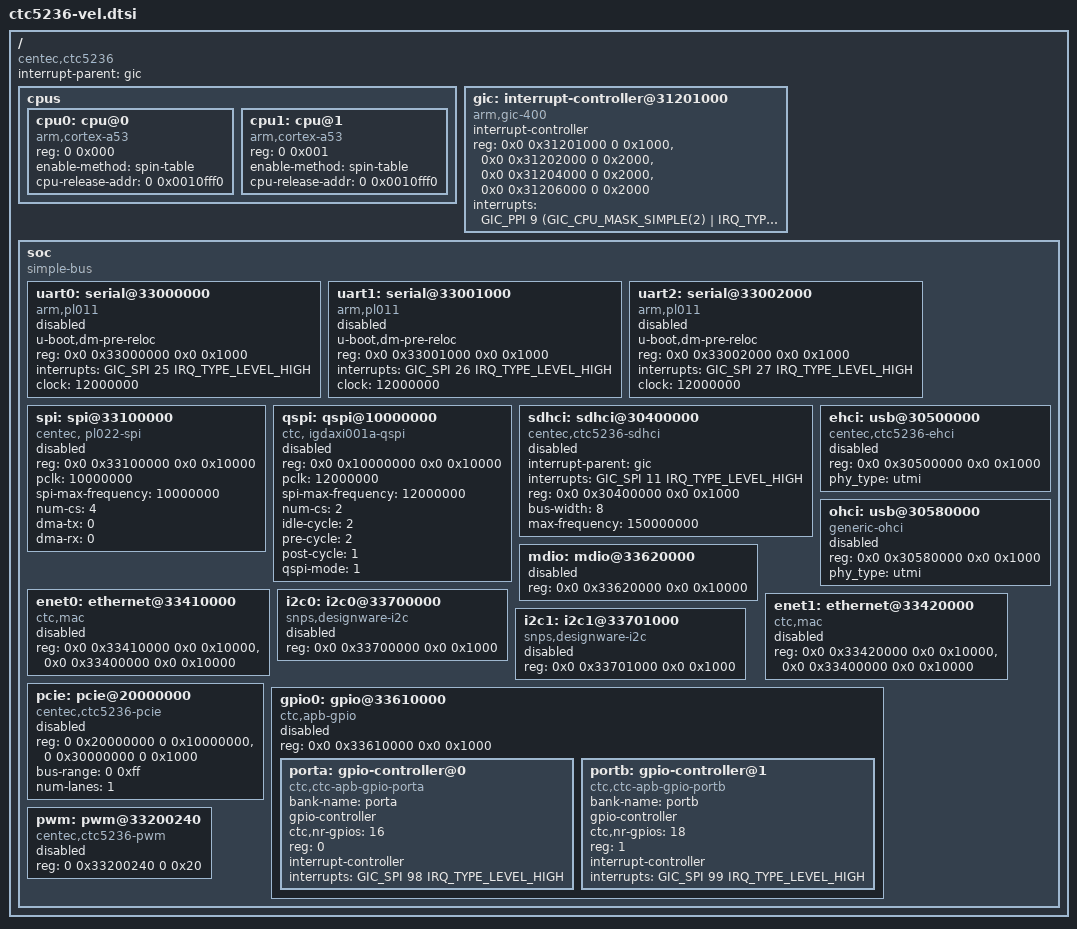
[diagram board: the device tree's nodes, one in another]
/*
 * dts file for Centec CTC5236(TsingMa) SoC
 *
 * (C) Copyright 2004-2017 Centec Networks (suzhou) Co., LTD.
 *
 * Jay Cao <caoj@centecnetworks.com>
 *
 * This program is free software; you can redistribute it and/or
 * modify it under the terms of the GNU General Public License as
 * published by the Free Software Foundation; either version 2 of
 * the License, or (at your option) any later version.
 */

#include <dt-bindings/interrupt-controller/arm-gic.h>
#include <dt-bindings/clock/ctc5236-clks.h>

/ {
	compatible = "centec,ctc5236";
	#address-cells = <2>;
	#size-cells = <2>;
	interrupt-parent = <&gic>;

	cpus {
		#address-cells = <2>;
		#size-cells = <0>;

		cpu0: cpu@0 {
			device_type = "cpu";
			compatible = "arm,cortex-a53", "arm,armv8";
			reg = <0 0x000>;
			enable-method = "spin-table";
			cpu-release-addr = <0 0x0010fff0>;
		};

		cpu1: cpu@1 {
			device_type = "cpu";
			compatible = "arm,cortex-a53", "arm,armv8";
			reg = <0 0x001>;
			enable-method = "spin-table";
			cpu-release-addr = <0 0x0010fff0>;
		};
	};
	
	gic: interrupt-controller@31201000 {
			compatible = "arm,gic-400";
			#interrupt-cells = <3>;
			interrupt-controller;
			reg = <0x0 0x31201000 0 0x1000>,
		  	      <0x0 0x31202000 0 0x2000>,
			      <0x0 0x31204000 0 0x2000>,
			      <0x0 0x31206000 0 0x2000>;
			interrupts = <GIC_PPI 9 (GIC_CPU_MASK_SIMPLE(2) | IRQ_TYPE_LEVEL_LOW)>;
                };

	soc: soc {
		compatible = "simple-bus";
		#address-cells = <2>;
		#size-cells = <2>;
		ranges;

		uart0: serial@33000000 {
			u-boot,dm-pre-reloc;
			compatible = "arm,pl011";
			status = "disabled";
			reg = <0x0 0x33000000 0x0 0x1000>;
			interrupts = <GIC_SPI 25 IRQ_TYPE_LEVEL_HIGH>;
			clock = <12000000>;
		};
		
		uart1: serial@33001000 {
			u-boot,dm-pre-reloc;
			compatible = "arm,pl011";
			status = "disabled";
			reg = <0x0 0x33001000 0x0 0x1000>;
			interrupts = <GIC_SPI 26 IRQ_TYPE_LEVEL_HIGH>;
			clock = <12000000>;
		};

		uart2: serial@33002000 {
			u-boot,dm-pre-reloc;
			compatible = "arm,pl011";
			status = "disabled";
			reg = <0x0 0x33002000 0x0 0x1000>;
			interrupts = <GIC_SPI 27 IRQ_TYPE_LEVEL_HIGH>;
			clock = <12000000>;
		};
		
		spi: spi@33100000 {
			compatible = "centec, pl022-spi";
			#address-cells = <1>;
			#size-cells = <0>;
			reg = <0x0 0x33100000 0x0 0x10000>;
			pclk = <10000000>;
			spi-max-frequency = <10000000>;
			num-cs = <4>;
			dma-tx = <0>;
			dma-rx = <0>;
			status = "disabled";
		};
		
		qspi: qspi@10000000 {
			compatible = "ctc, igdaxi001a-qspi";
			#address-cells = <1>;
			#size-cells = <0>;
			reg = <0x0 0x10000000 0x0 0x10000>;
			pclk = <12000000>;
			spi-max-frequency = <12000000>;
			num-cs = <2>;
			status = "disabled";
			idle-cycle = <2>;
			pre-cycle = <2>;
			post-cycle = <1>;
			qspi-mode = <1>;   
		};
		
		sdhci: sdhci@30400000 {
			compatible = "centec,ctc5236-sdhci";
			status = "disabled";
			interrupt-parent = <&gic>;
			interrupts = <GIC_SPI 11 IRQ_TYPE_LEVEL_HIGH>;
			reg = <0x0 0x30400000 0x0 0x1000>;
			bus-width = <8>;
			max-frequency = <150000000>;
		};

		ehci: usb@30500000 {
			compatible = "centec,ctc5236-ehci";
			status = "disabled";
			reg = <0x0 0x30500000 0x0 0x1000>;
			phy_type = "utmi";
		};

		ohci: usb@30580000 {
			compatible = "generic-ohci";
			status = "disabled";
			reg = <0x0 0x30580000 0x0 0x1000>;
			phy_type = "utmi";
		};

		mdio: mdio@33620000 {
			#address-cells = <1>;
			#size-cells = <0>;
			reg = <0x0 0x33620000 0x0 0x10000>;
			status = "disabled";
		};
					
		enet0: ethernet@33410000 {
			compatible = "ctc,mac";
			reg = <0x0 0x33410000 0x0 0x10000>,
				<0x0 0x33400000 0x0 0x10000>;
			status = "disabled";
		};
			
		enet1: ethernet@33420000 {
			compatible = "ctc,mac";
			reg = <0x0 0x33420000 0x0 0x10000>,
				<0x0 0x33400000 0x0 0x10000>;
			status = "disabled";
		};
			
		i2c0: i2c0@33700000{
				#address-cells = <1>;
				#size-cells = <0>;
				compatible = "snps,designware-i2c";
				reg = <0x0 0x33700000 0x0 0x1000>;
				status = "disabled";
		};
		
		i2c1: i2c1@33701000 {
				compatible = "snps,designware-i2c";
				reg = <0x0 0x33701000 0x0 0x1000>;
				status = "disabled";
		};

		pcie: pcie@20000000 {
				compatible = "centec,ctc5236-pcie";
				reg =	<0 0x20000000 0 0x10000000>,
					<0 0x30000000 0 0x1000>;
				reg-names = "cfg", "ctrl";
				#address-cells = <3>;
				#size-cells = <2>;
				#interrupt-cells = <1>;
				device_type = "pci";

				bus-range = <0 0xff>;
				ranges = <0x42000000 0 0x00000000 0  0x40000000 0 0x40000000>;
				num-lanes = <1>;
				status = "disabled";
        };

		gpio0: gpio@33610000 {
			#address-cells = <1>;
			#size-cells = <0>;
			compatible = "ctc,apb-gpio"; 
			reg = <0x0 0x33610000 0x0 0x1000>;
			status = "disabled";

			porta: gpio-controller@0 {
				compatible = "ctc,ctc-apb-gpio-porta";
				bank-name = "porta";
				gpio-controller;
				#gpio-cells = <2>;
				ctc,nr-gpios = <16>;
				reg = <0>;
				interrupt-controller;
				#interrupt-cells = <2>;
				interrupts = <GIC_SPI 98 IRQ_TYPE_LEVEL_HIGH>;
			};

			portb: gpio-controller@1 {
				compatible = "ctc,ctc-apb-gpio-portb";
				bank-name = "portb";
				gpio-controller;
				#gpio-cells = <2>;
				ctc,nr-gpios = <18>;
				reg = <1>;
				interrupt-controller;
				#interrupt-cells = <2>;
				interrupts = <GIC_SPI 99 IRQ_TYPE_LEVEL_HIGH>;
			};
		};
		
				
		pwm: pwm@33200240{
			#address-cells = <1>;
			#size-cells = <0>;
			compatible = "centec,ctc5236-pwm";
			reg = <0 0x33200240 0 0x20>;
			status = "disabled";
		};		
	};
};

